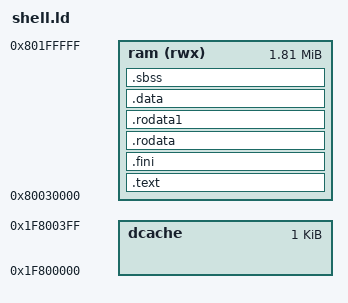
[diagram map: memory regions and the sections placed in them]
/*

MIT License

Copyright (c) 2019 PCSX-Redux authors

Permission is hereby granted, free of charge, to any person obtaining a copy
of this software and associated documentation files (the "Software"), to deal
in the Software without restriction, including without limitation the rights
to use, copy, modify, merge, publish, distribute, sublicense, and/or sell
copies of the Software, and to permit persons to whom the Software is
furnished to do so, subject to the following conditions:

The above copyright notice and this permission notice shall be included in all
copies or substantial portions of the Software.

THE SOFTWARE IS PROVIDED "AS IS", WITHOUT WARRANTY OF ANY KIND, EXPRESS OR
IMPLIED, INCLUDING BUT NOT LIMITED TO THE WARRANTIES OF MERCHANTABILITY,
FITNESS FOR A PARTICULAR PURPOSE AND NONINFRINGEMENT. IN NO EVENT SHALL THE
AUTHORS OR COPYRIGHT HOLDERS BE LIABLE FOR ANY CLAIM, DAMAGES OR OTHER
LIABILITY, WHETHER IN AN ACTION OF CONTRACT, TORT OR OTHERWISE, ARISING FROM,
OUT OF OR IN CONNECTION WITH THE SOFTWARE OR THE USE OR OTHER DEALINGS IN THE
SOFTWARE.

*/

OUTPUT_FORMAT("elf32-tradlittlemips")
OUTPUT_ARCH(mips)

EXTERN(_start)
ENTRY(_start)

MEMORY {
    ram (rwx)   : ORIGIN = 0x80030000, LENGTH = 2M - 0x30000
    dcache      : ORIGIN = 0x1f800000, LENGTH = 0x400
}

__ram_top       = ORIGIN(ram) + LENGTH(ram);
__sp            = __ram_top - 0x100;

__dcache        = ORIGIN(dcache);
__dcache_top    = ORIGIN(dcache) + LENGTH(dcache);

__bss_len       = (__bss_end - __bss_start);

SECTIONS {
    __text_start = .;
    .text : {
        *(.start)
        *(.init)
        KEEP (*(SORT_NONE(.fini)))
        *(.text.unlikely .text.*_unlikely .text.unlikely.*)
        *(.text.exit .text.exit.*)
        *(.text.startup .text.startup.*)
        *(.text.hot .text.hot.*)
        *(.text .stub .text.* .gnu.linkonce.t.*)
        . = ALIGN(4);
    } > ram

    .fini : {
    } > ram
    . = ALIGN(4);
    __text_end = .;

    .rodata : {
        *(.rodata .rodata.* .rdata .rdata.* .gnu.linkonce.r.*)
    } > ram

    .rodata1 : {
        *(.rodata1)
    } > ram

    __data_start = .;
    .data : {
        *(.a0table)
        *(.data .data.* .gnu.linkonce.d.*)
        *(.data1)
        *(.got.plt)
        *(.got)
    } > ram

    . = ALIGN(4);

    __bss_start = .;
    .sbss : {
        *(.dynsbss)
        *(.sbss .sbss.* .gnu.linkonce.sb.*)
        *(.scommon)
        *(.dynbss)
        *(.bss .bss.* .gnu.linkonce.b.*)
        *(COMMON)
    } > ram

    . = ALIGN(4);
    __bss_end = .;

    __end = .;

    /DISCARD/ : { *(.MIPS.abiflags) }

    /* Everything is statically linked, so discard PLTs. */
    /DISCARD/ : { *(.rel.iplt) *(.rela.iplt) *(.rel.plt) *(.rela.plt) *(.plt) *(.iplt) }

    /* Discard things that the standard link script drops, too. */
    /DISCARD/ : { *(.note.GNU-stack) *(.gnu_debuglink) *(.gnu.lto_*) }

    /DISCARD/ : { *(.note.gnu.build-id) }
}
